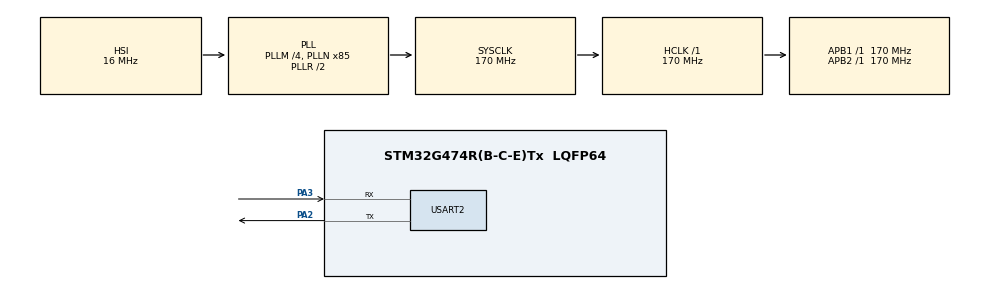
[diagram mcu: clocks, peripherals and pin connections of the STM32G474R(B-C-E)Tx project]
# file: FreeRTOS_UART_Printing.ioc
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FREERTOS.Mutexes01=uartMutex,Dynamic,NULL,Available
FREERTOS.Tasks01=Task1,24,128,StartTask1,Default,NULL,Dynamic,NULL,NULL;Task2,24,128,StartTask2,Default,NULL,Dynamic,NULL,NULL;Task3,24,128,StartTask3,Default,NULL,Dynamic,NULL,NULL
Mcu.Family=STM32G4
Mcu.Name=STM32G474R(B-C-E)Tx
Mcu.Package=LQFP64
NVIC.PriorityGroup=NVIC_PRIORITYGROUP_4
NVIC.TIM4_IRQn=true\:15\:0\:false\:false\:true\:false\:false\:true\:true
NVIC.TimeBase=TIM4_IRQn
NVIC.TimeBaseIP=TIM4
PA13.Mode=Serial_Wire
PA13.Signal=SYS_JTMS-SWDIO
PA14.Mode=Serial_Wire
PA14.Signal=SYS_JTCK-SWCLK
PA2.Mode=Asynchronous
PA2.Signal=USART2_TX
PA3.Mode=Asynchronous
PA3.Signal=USART2_RX
ProjectManager.HeapSize=0x200
ProjectManager.StackSize=0x400
ProjectManager.TargetToolchain=STM32CubeIDE
RCC.ADC12Freq_Value=170000000
RCC.ADC345Freq_Value=170000000
RCC.AHBFreq_Value=170000000
RCC.APB1Freq_Value=170000000
RCC.APB1TimFreq_Value=170000000
RCC.APB2Freq_Value=170000000
RCC.APB2TimFreq_Value=170000000
RCC.CortexFreq_Value=170000000
RCC.EXTERNAL_CLOCK_VALUE=12288000
RCC.HCLKFreq_Value=170000000
RCC.HSE_VALUE=24000000
RCC.HSI48_VALUE=48000000
RCC.HSI_VALUE=16000000
RCC.LSE_VALUE=32768
RCC.PLLM=RCC_PLLM_DIV4
RCC.PLLN=85
RCC.RTCClockSelection=RCC_RTCCLKSOURCE_LSE
RCC.SYSCLKFreq_VALUE=170000000
RCC.SYSCLKSource=RCC_SYSCLKSOURCE_PLLCLK
RCC.USBFreq_Value=170000000
RCC.VCOOutputFreq_Value=340000000
USART2.VirtualMode-Asynchronous=VM_ASYNC
VP_FREERTOS_VS_CMSIS_V2.Mode=CMSIS_V2
VP_SYS_VS_DBSignals.Mode=DisableDeadBatterySignals
VP_SYS_VS_tim4.Mode=TIM4
board=NUCLEO-G474RE

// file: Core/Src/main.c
/* USER CODE BEGIN Header */
/**
  ******************************************************************************
  * @file           : main.c
  * @brief          : Main program body
  ******************************************************************************
  * @attention
  *
  * Copyright (c) 2026 STMicroelectronics.
  * All rights reserved.
  *
  * This software is licensed under terms that can be found in the LICENSE file
  * in the root directory of this software component.
  * If no LICENSE file comes with this software, it is provided AS-IS.
  *
  ******************************************************************************
  */
/* USER CODE END Header */
#include "main.h"
#include "cmsis_os.h"

/* USER CODE BEGIN Includes */
#include "string.h"
/* USER CODE END Includes */

UART_HandleTypeDef huart2;

/* Definitions for Task1 */
osThreadId_t Task1Handle;
const osThreadAttr_t Task1_attributes = {
  .name = "Task1",
  .priority = (osPriority_t) osPriorityNormal,
  .stack_size = 128 * 4
};
/* Definitions for Task2 */
osThreadId_t Task2Handle;
const osThreadAttr_t Task2_attributes = {
  .name = "Task2",
  .priority = (osPriority_t) osPriorityNormal,
  .stack_size = 128 * 4
};
/* Definitions for Task3 */
osThreadId_t Task3Handle;
const osThreadAttr_t Task3_attributes = {
  .name = "Task3",
  .priority = (osPriority_t) osPriorityNormal,
  .stack_size = 128 * 4
};
/* Definitions for uartMutex */
osMutexId_t uartMutexHandle;
const osMutexAttr_t uartMutex_attributes = {
  .name = "uartMutex"
};

void SystemClock_Config(void);
static void MX_GPIO_Init(void);
static void MX_USART2_UART_Init(void);
void StartTask1(void *argument);
void StartTask2(void *argument);
void StartTask3(void *argument);

int main(void)
{

  /* MCU Configuration--------------------------------------------------------*/

  /* Reset of all peripherals, Initializes the Flash interface and the Systick. */
  HAL_Init();

  /* Configure the system clock */
  SystemClock_Config();

  /* Initialize all configured peripherals */
  MX_GPIO_Init();
  MX_USART2_UART_Init();

  /* Init scheduler */
  osKernelInitialize();
  /* Create the mutex(es) */
  /* creation of uartMutex */
  uartMutexHandle = osMutexNew(&uartMutex_attributes);

  /* Create the thread(s) */
  /* creation of Task1 */
  Task1Handle = osThreadNew(StartTask1, NULL, &Task1_attributes);

  /* creation of Task2 */
  Task2Handle = osThreadNew(StartTask2, NULL, &Task2_attributes);

  /* creation of Task3 */
  Task3Handle = osThreadNew(StartTask3, NULL, &Task3_attributes);

  /* Start scheduler */
  osKernelStart();

  /* We should never get here as control is now taken by the scheduler */

  /* Infinite loop */
  while (1)
  {

  }
}

void SystemClock_Config(void)
{
  RCC_OscInitTypeDef RCC_OscInitStruct = {0};
  RCC_ClkInitTypeDef RCC_ClkInitStruct = {0};

  /** Configure the main internal regulator output voltage
  */
  HAL_PWREx_ControlVoltageScaling(PWR_REGULATOR_VOLTAGE_SCALE1_BOOST);

  /** Initializes the RCC Oscillators according to the specified parameters
  * in the RCC_OscInitTypeDef structure.
  */
  RCC_OscInitStruct.OscillatorType = RCC_OSCILLATORTYPE_HSI;
  RCC_OscInitStruct.HSIState = RCC_HSI_ON;
  RCC_OscInitStruct.HSICalibrationValue = RCC_HSICALIBRATION_DEFAULT;
  RCC_OscInitStruct.PLL.PLLState = RCC_PLL_ON;
  RCC_OscInitStruct.PLL.PLLSource = RCC_PLLSOURCE_HSI;
  RCC_OscInitStruct.PLL.PLLM = RCC_PLLM_DIV4;
  RCC_OscInitStruct.PLL.PLLN = 85;
  RCC_OscInitStruct.PLL.PLLP = RCC_PLLP_DIV2;
  RCC_OscInitStruct.PLL.PLLQ = RCC_PLLQ_DIV2;
  RCC_OscInitStruct.PLL.PLLR = RCC_PLLR_DIV2;
  if (HAL_RCC_OscConfig(&RCC_OscInitStruct) != HAL_OK)
  {
    Error_Handler();
  }

  /** Initializes the CPU, AHB and APB buses clocks
  */
  RCC_ClkInitStruct.ClockType = RCC_CLOCKTYPE_HCLK|RCC_CLOCKTYPE_SYSCLK
                              |RCC_CLOCKTYPE_PCLK1|RCC_CLOCKTYPE_PCLK2;
  RCC_ClkInitStruct.SYSCLKSource = RCC_SYSCLKSOURCE_PLLCLK;
  RCC_ClkInitStruct.AHBCLKDivider = RCC_SYSCLK_DIV1;
  RCC_ClkInitStruct.APB1CLKDivider = RCC_HCLK_DIV1;
  RCC_ClkInitStruct.APB2CLKDivider = RCC_HCLK_DIV1;

  if (HAL_RCC_ClockConfig(&RCC_ClkInitStruct, FLASH_LATENCY_4) != HAL_OK)
  {
    Error_Handler();
  }
}

static void MX_USART2_UART_Init(void)
{

  huart2.Instance = USART2;
  huart2.Init.BaudRate = 115200;
  huart2.Init.WordLength = UART_WORDLENGTH_8B;
  huart2.Init.StopBits = UART_STOPBITS_1;
  huart2.Init.Parity = UART_PARITY_NONE;
  huart2.Init.Mode = UART_MODE_TX_RX;
  huart2.Init.HwFlowCtl = UART_HWCONTROL_NONE;
  huart2.Init.OverSampling = UART_OVERSAMPLING_16;
  huart2.Init.OneBitSampling = UART_ONE_BIT_SAMPLE_DISABLE;
  huart2.Init.ClockPrescaler = UART_PRESCALER_DIV1;
  huart2.AdvancedInit.AdvFeatureInit = UART_ADVFEATURE_NO_INIT;
  if (HAL_UART_Init(&huart2) != HAL_OK)
  {
    Error_Handler();
  }
  if (HAL_UARTEx_SetTxFifoThreshold(&huart2, UART_TXFIFO_THRESHOLD_1_8) != HAL_OK)
  {
    Error_Handler();
  }
  if (HAL_UARTEx_SetRxFifoThreshold(&huart2, UART_RXFIFO_THRESHOLD_1_8) != HAL_OK)
  {
    Error_Handler();
  }
  if (HAL_UARTEx_DisableFifoMode(&huart2) != HAL_OK)
  {
    Error_Handler();
  }

}

static void MX_GPIO_Init(void)
{

  /* GPIO Ports Clock Enable */
  __HAL_RCC_GPIOA_CLK_ENABLE();

}

void StartTask1(void *argument)
{
  /* USER CODE BEGIN 5 */
  /* Infinite loop */
	char *msg = "Task1 Running\r\n";
	for(;;)
	{
		osMutexAcquire(uartMutexHandle, osWaitForever);

		HAL_UART_Transmit(&huart2,(uint8_t*)msg, strlen(msg), HAL_MAX_DELAY);

		osMutexRelease(uartMutexHandle);

		osDelay(500);
	}
  /* USER CODE END 5 */
}

void StartTask2(void *argument)
{
  /* USER CODE BEGIN StartTask2 */
  /* Infinite loop */
	char *msg = "Task2 Running\r\n";
	for(;;)
	{
		osMutexAcquire(uartMutexHandle, osWaitForever);

		HAL_UART_Transmit(&huart2,(uint8_t*)msg, strlen(msg), HAL_MAX_DELAY);

		osMutexRelease(uartMutexHandle);

		osDelay(1000);
	}
  /* USER CODE END StartTask2 */
}

void StartTask3(void *argument)
{
  /* USER CODE BEGIN StartTask3 */
  /* Infinite loop */
	char *msg = "Task3 Running\r\n";
	for(;;)
	{
		osMutexAcquire(uartMutexHandle, osWaitForever);

		HAL_UART_Transmit(&huart2,(uint8_t*)msg, strlen(msg), HAL_MAX_DELAY);

		osMutexRelease(uartMutexHandle);

		osDelay(1500);
	}
  /* USER CODE END StartTask3 */
}

void HAL_TIM_PeriodElapsedCallback(TIM_HandleTypeDef *htim)
{
  if (htim->Instance == TIM4)
  {
    HAL_IncTick();
  }
}

void Error_Handler(void)
{
  __disable_irq();
  while (1)
  {
  }
}
